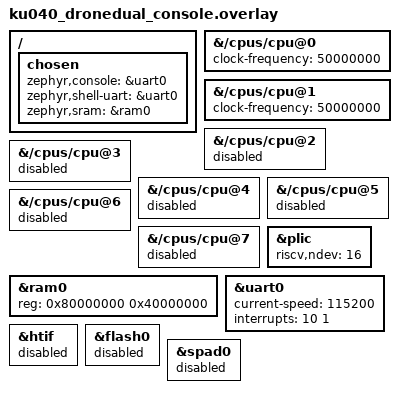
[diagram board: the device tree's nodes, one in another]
/*
 * Real-hardware overlay for RocketKU040DroneDualConfig, values verified
 * against the actual generated DTS (elaborated today on the garden):
 *   /scratch/dima/riskybird_chipyard/fpga/generated-src/chipyard.fpga.ku040.KU040Harness.RocketKU040DroneDualConfig/chipyard.fpga.ku040.KU040Harness.RocketKU040DroneDualConfig.dts
 *
 * Confirmed directly from that file (not taken on faith):
 *   - cpus { timebase-frequency = <50000>; }, pbus/peripheral clocks all
 *     50000000 (50 MHz) -- cpu@0/cpu@1 clock-frequency in the raw DTS is
 *     "0" (Rocket leaves it to the external clock ref), so we pin it to
 *     50000000 here for Zephyr's own timer/baud math.
 *   - serial@10020000 (uart0): interrupts = <10>  (NOT 3 -- the stock
 *     Zephyr chipyard-riscv.dtsi's <3 1> is wrong for this real hardware)
 *   - serial@10021000 (uart1): interrupts = <11>
 *   - plic: riscv,ndev = <16>
 *   - memory@80000000: reg = <0x80000000 0x40000000>  (1 GiB)
 *   - memory@8000000 (spad-equivalent): status = "disabled" in the real DTS
 */

/ { chosen { zephyr,console = &uart0; zephyr,shell-uart = &uart0; zephyr,sram = &ram0; }; };

&{/cpus/cpu@0} { clock-frequency = <50000000>; };
&{/cpus/cpu@1} { clock-frequency = <50000000>; status = "okay"; };
&{/cpus/cpu@2} { status = "disabled"; };
&{/cpus/cpu@3} { status = "disabled"; };
&{/cpus/cpu@4} { status = "disabled"; };
&{/cpus/cpu@5} { status = "disabled"; };
&{/cpus/cpu@6} { status = "disabled"; };
&{/cpus/cpu@7} { status = "disabled"; };

&plic  { riscv,ndev = <16>; };
&ram0  { reg = <0x80000000 0x40000000>; status = "okay"; };
&uart0 { status = "okay"; current-speed = <115200>; interrupts = <10 1>; };
&htif  { status = "disabled"; };
&flash0 { status = "disabled"; };
&spad0 { status = "disabled"; };
